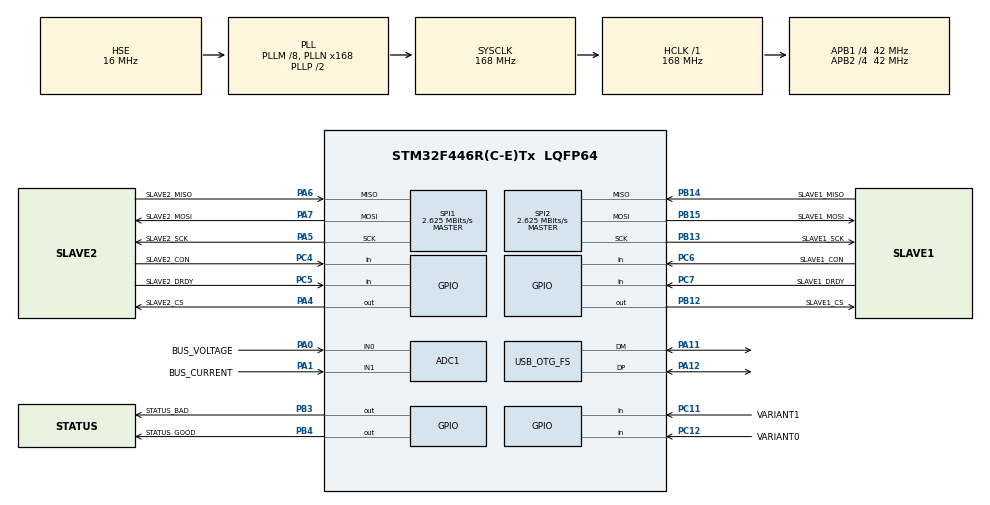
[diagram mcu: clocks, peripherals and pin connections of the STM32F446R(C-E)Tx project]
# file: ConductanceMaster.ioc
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ADC1.Channel-0\#ChannelRegularConversion=ADC_CHANNEL_0
ADC1.Channel-1\#ChannelRegularConversion=ADC_CHANNEL_1
ADC1.Channel-2\#ChannelRegularConversion=ADC_CHANNEL_TEMPSENSOR
ADC1.Channel-3\#ChannelRegularConversion=ADC_CHANNEL_VREFINT
ADC1.ClockPrescaler=ADC_CLOCK_SYNC_PCLK_DIV8
ADC1.ContinuousConvMode=DISABLE
ADC1.DiscontinuousConvMode=DISABLE
ADC1.EOCSelection=ADC_EOC_SEQ_CONV
ADC1.NbrOfConversion=4
ADC1.NbrOfConversionFlag=1
ADC1.Rank-0\#ChannelRegularConversion=1
ADC1.Rank-1\#ChannelRegularConversion=2
ADC1.Rank-2\#ChannelRegularConversion=3
ADC1.Rank-3\#ChannelRegularConversion=4
ADC1.SamplingTime-0\#ChannelRegularConversion=ADC_SAMPLETIME_480CYCLES
ADC1.SamplingTime-1\#ChannelRegularConversion=ADC_SAMPLETIME_480CYCLES
ADC1.SamplingTime-2\#ChannelRegularConversion=ADC_SAMPLETIME_480CYCLES
ADC1.SamplingTime-3\#ChannelRegularConversion=ADC_SAMPLETIME_480CYCLES
ADC1.master=1
Dma.ADC1.0.Direction=DMA_PERIPH_TO_MEMORY
Dma.ADC1.0.FIFOMode=DMA_FIFOMODE_DISABLE
Dma.ADC1.0.Instance=DMA2_Stream0
Dma.ADC1.0.MemDataAlignment=DMA_MDATAALIGN_HALFWORD
Dma.ADC1.0.MemInc=DMA_MINC_ENABLE
Dma.ADC1.0.Mode=DMA_NORMAL
Dma.ADC1.0.PeriphDataAlignment=DMA_PDATAALIGN_HALFWORD
Dma.ADC1.0.PeriphInc=DMA_PINC_DISABLE
Dma.ADC1.0.Priority=DMA_PRIORITY_LOW
Dma.Request0=ADC1
Mcu.Family=STM32F4
Mcu.Name=STM32F446R(C-E)Tx
Mcu.Package=LQFP64
NVIC.DMA2_Stream0_IRQn=true\:0\:0\:false\:false\:true\:false\:true\:true
NVIC.OTG_FS_IRQn=true\:0\:0\:false\:false\:true\:false\:true\:true
NVIC.PriorityGroup=NVIC_PRIORITYGROUP_4
NVIC.TIM1_UP_TIM10_IRQn=true\:0\:0\:false\:false\:true\:true\:true\:true
PA0-WKUP.GPIO_Label=BUS_VOLTAGE
PA0-WKUP.Signal=ADCx_IN0
PA1.GPIO_Label=BUS_CURRENT
PA1.Signal=ADCx_IN1
PA11.Mode=Device_Only
PA11.Signal=USB_OTG_FS_DM
PA12.Mode=Device_Only
PA12.Signal=USB_OTG_FS_DP
PA13.Mode=Serial_Wire
PA13.Signal=SYS_JTMS-SWDIO
PA14.Mode=Serial_Wire
PA14.Signal=SYS_JTCK-SWCLK
PA4.GPIO_Label=SLAVE2_CS
PA4.PinState=GPIO_PIN_SET
PA4.Signal=GPIO_Output
PA5.GPIO_Label=SLAVE2_SCK
PA5.Mode=Full_Duplex_Master
PA5.Signal=SPI1_SCK
PA6.GPIO_Label=SLAVE2_MISO
PA6.Mode=Full_Duplex_Master
PA6.Signal=SPI1_MISO
PA7.GPIO_Label=SLAVE2_MOSI
PA7.Mode=Full_Duplex_Master
PA7.Signal=SPI1_MOSI
PB12.GPIO_Label=SLAVE1_CS
PB12.PinState=GPIO_PIN_SET
PB12.Signal=GPIO_Output
PB13.GPIO_Label=SLAVE1_SCK
PB13.Mode=Full_Duplex_Master
PB13.Signal=SPI2_SCK
PB14.GPIO_Label=SLAVE1_MISO
PB14.Mode=Full_Duplex_Master
PB14.Signal=SPI2_MISO
PB15.GPIO_Label=SLAVE1_MOSI
PB15.Mode=Full_Duplex_Master
PB15.Signal=SPI2_MOSI
PB3.GPIO_Label=STATUS_BAD
PB3.GPIO_ModeDefaultOutputPP=GPIO_MODE_OUTPUT_OD
PB3.GPIO_PuPd=GPIO_NOPULL
PB3.PinState=GPIO_PIN_SET
PB3.Signal=GPIO_Output
PB4.GPIO_Label=STATUS_GOOD
PB4.GPIO_ModeDefaultOutputPP=GPIO_MODE_OUTPUT_OD
PB4.GPIO_PuPd=GPIO_NOPULL
PB4.PinState=GPIO_PIN_SET
PB4.Signal=GPIO_Output
PC11.GPIO_Label=VARIANT1
PC11.GPIO_PuPd=GPIO_PULLUP
PC11.Signal=GPIO_Input
PC12.GPIO_Label=VARIANT0
PC12.GPIO_PuPd=GPIO_PULLUP
PC12.Signal=GPIO_Input
PC4.GPIO_Label=SLAVE2_CON
PC4.GPIO_PuPd=GPIO_PULLUP
PC4.Signal=GPIO_Input
PC5.GPIO_Label=SLAVE2_DRDY
PC5.GPIO_PuPd=GPIO_PULLUP
PC5.Signal=GPIO_Input
PC6.GPIO_Label=SLAVE1_CON
PC6.GPIO_PuPd=GPIO_PULLUP
PC6.Signal=GPIO_Input
PC7.GPIO_Label=SLAVE1_DRDY
PC7.GPIO_PuPd=GPIO_PULLUP
PC7.Signal=GPIO_Input
PH0-OSC_IN.Mode=HSE-External-Clock-Source
PH0-OSC_IN.Signal=RCC_OSC_IN
PH1-OSC_OUT.Mode=HSE-External-Clock-Source
PH1-OSC_OUT.Signal=RCC_OSC_OUT
ProjectManager.HeapSize=0x200
ProjectManager.StackSize=0x400
ProjectManager.TargetToolchain=STM32CubeIDE
RCC.AHBFreq_Value=168000000
RCC.APB1CLKDivider=RCC_HCLK_DIV4
RCC.APB1Freq_Value=42000000
RCC.APB1TimFreq_Value=84000000
RCC.APB2CLKDivider=RCC_HCLK_DIV4
RCC.APB2Freq_Value=42000000
RCC.APB2TimFreq_Value=84000000
RCC.CortexFreq_Value=168000000
RCC.HCLKFreq_Value=168000000
RCC.HSE_VALUE=16000000
RCC.PLLM=8
RCC.PLLN=168
RCC.PLLQ=7
RCC.SYSCLKFreq_VALUE=168000000
RCC.SYSCLKSource=RCC_SYSCLKSOURCE_PLLCLK
RCC.USBFreq_Value=48000000
RCC.VCOOutputFreq_Value=336000000
SH.ADCx_IN0.0=ADC1_IN0,IN0
SH.ADCx_IN1.0=ADC1_IN1,IN1
SPI1.BaudRatePrescaler=SPI_BAUDRATEPRESCALER_16
SPI1.CalculateBaudRate=2.625 MBits/s
SPI1.DataSize=SPI_DATASIZE_16BIT
SPI1.Direction=SPI_DIRECTION_2LINES
SPI1.Mode=SPI_MODE_MASTER
SPI1.VirtualType=VM_MASTER
SPI2.BaudRatePrescaler=SPI_BAUDRATEPRESCALER_16
SPI2.CalculateBaudRate=2.625 MBits/s
SPI2.DataSize=SPI_DATASIZE_16BIT
SPI2.Direction=SPI_DIRECTION_2LINES
SPI2.Mode=SPI_MODE_MASTER
SPI2.VirtualType=VM_MASTER
TIM1.Period=99
TIM1.Prescaler=83
USB_DEVICE.CLASS_NAME_FS=CUSTOM_HID
USB_DEVICE.CONFIGURATION_STRING_CUSTOMHID_FS=Conductance Config
USB_DEVICE.INTERFACE_STRING_CUSTOMHID_FS=Conductance Interface
USB_DEVICE.MANUFACTURER_STRING-CUSTOM_HID_FS=H-BRS/ISF
USB_DEVICE.PRODUCT_STRING_CUSTOMHID_FS=Conductance Board
USB_DEVICE.USBD_SELF_POWERED-CUSTOM_HID_FS=0
USB_DEVICE.VirtualMode-CUSTOM_HID_FS=CustomHid
USB_DEVICE.VirtualModeFS=Custom_Hid_FS
USB_OTG_FS.VirtualMode=Device_Only
VP_ADC1_TempSens_Input.Mode=IN-TempSens
VP_ADC1_Vref_Input.Mode=IN-Vrefint
VP_TIM1_VS_ClockSourceINT.Mode=Internal
VP_USB_DEVICE_VS_USB_DEVICE_CUSTOM_HID_FS.Mode=CUSTOM_HID_FS
board=custom

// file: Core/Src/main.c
/* USER CODE BEGIN Header */
/**
  ******************************************************************************
  * @file           : main.c
  * @brief          : Main program body
  ******************************************************************************
  * @attention
  *
  * <h2><center>&copy; Copyright (c) 2021 STMicroelectronics.
  * All rights reserved.</center></h2>
  *
  * This software component is licensed by ST under BSD 3-Clause license,
  * the "License"; You may not use this file except in compliance with the
  * License. You may obtain a copy of the License at:
  *                        opensource.org/licenses/BSD-3-Clause
  *
  ******************************************************************************
  */
/* USER CODE END Header */
#include "main.h"
#include "usb_device.h"

/* USER CODE BEGIN Includes */
#include "usermain.h"
/* USER CODE END Includes */

ADC_HandleTypeDef hadc1;
DMA_HandleTypeDef hdma_adc1;

SPI_HandleTypeDef hspi1;
SPI_HandleTypeDef hspi2;

TIM_HandleTypeDef htim1;

void SystemClock_Config(void);
static void MX_GPIO_Init(void);
static void MX_DMA_Init(void);
static void MX_ADC1_Init(void);
static void MX_SPI1_Init(void);
static void MX_SPI2_Init(void);
static void MX_TIM1_Init(void);

int main(void)
{

  /* MCU Configuration--------------------------------------------------------*/

  /* Reset of all peripherals, Initializes the Flash interface and the Systick. */
  HAL_Init();

  /* Configure the system clock */
  SystemClock_Config();

  /* Initialize all configured peripherals */
  MX_GPIO_Init();
  MX_DMA_Init();
  MX_SPI1_Init();
  MX_SPI2_Init();
  MX_TIM1_Init();
  MX_USB_DEVICE_Init();
  /* USER CODE BEGIN 2 */
  MX_ADC1_Init(); // Must be called after MX_DMA_Init()
  user_main();
  /* USER CODE END 2 */

  /* Infinite loop */
  while (1)
  {

  }
}

void SystemClock_Config(void)
{
  RCC_OscInitTypeDef RCC_OscInitStruct = {0};
  RCC_ClkInitTypeDef RCC_ClkInitStruct = {0};

  /** Configure the main internal regulator output voltage
  */
  __HAL_RCC_PWR_CLK_ENABLE();
  __HAL_PWR_VOLTAGESCALING_CONFIG(PWR_REGULATOR_VOLTAGE_SCALE1);

  /** Initializes the RCC Oscillators according to the specified parameters
  * in the RCC_OscInitTypeDef structure.
  */
  RCC_OscInitStruct.OscillatorType = RCC_OSCILLATORTYPE_HSE;
  RCC_OscInitStruct.HSEState = RCC_HSE_BYPASS;
  RCC_OscInitStruct.PLL.PLLState = RCC_PLL_ON;
  RCC_OscInitStruct.PLL.PLLSource = RCC_PLLSOURCE_HSE;
  RCC_OscInitStruct.PLL.PLLM = 8;
  RCC_OscInitStruct.PLL.PLLN = 168;
  RCC_OscInitStruct.PLL.PLLP = RCC_PLLP_DIV2;
  RCC_OscInitStruct.PLL.PLLQ = 7;
  RCC_OscInitStruct.PLL.PLLR = 2;
  if (HAL_RCC_OscConfig(&RCC_OscInitStruct) != HAL_OK)
  {
    Error_Handler();
  }

  /** Initializes the CPU, AHB and APB buses clocks
  */
  RCC_ClkInitStruct.ClockType = RCC_CLOCKTYPE_HCLK|RCC_CLOCKTYPE_SYSCLK
                              |RCC_CLOCKTYPE_PCLK1|RCC_CLOCKTYPE_PCLK2;
  RCC_ClkInitStruct.SYSCLKSource = RCC_SYSCLKSOURCE_PLLCLK;
  RCC_ClkInitStruct.AHBCLKDivider = RCC_SYSCLK_DIV1;
  RCC_ClkInitStruct.APB1CLKDivider = RCC_HCLK_DIV4;
  RCC_ClkInitStruct.APB2CLKDivider = RCC_HCLK_DIV4;

  if (HAL_RCC_ClockConfig(&RCC_ClkInitStruct, FLASH_LATENCY_5) != HAL_OK)
  {
    Error_Handler();
  }
}

static void MX_ADC1_Init(void)
{

  ADC_ChannelConfTypeDef sConfig = {0};

  /** Configure the global features of the ADC (Clock, Resolution, Data Alignment and number of conversion)
  */
  hadc1.Instance = ADC1;
  hadc1.Init.ClockPrescaler = ADC_CLOCK_SYNC_PCLK_DIV8;
  hadc1.Init.Resolution = ADC_RESOLUTION_12B;
  hadc1.Init.ScanConvMode = ENABLE;
  hadc1.Init.ContinuousConvMode = DISABLE;
  hadc1.Init.DiscontinuousConvMode = DISABLE;
  hadc1.Init.ExternalTrigConvEdge = ADC_EXTERNALTRIGCONVEDGE_NONE;
  hadc1.Init.ExternalTrigConv = ADC_SOFTWARE_START;
  hadc1.Init.DataAlign = ADC_DATAALIGN_RIGHT;
  hadc1.Init.NbrOfConversion = 4;
  hadc1.Init.DMAContinuousRequests = DISABLE;
  hadc1.Init.EOCSelection = ADC_EOC_SEQ_CONV;
  if (HAL_ADC_Init(&hadc1) != HAL_OK)
  {
    Error_Handler();
  }

  /** Configure for the selected ADC regular channel its corresponding rank in the sequencer and its sample time.
  */
  sConfig.Channel = ADC_CHANNEL_0;
  sConfig.Rank = 1;
  sConfig.SamplingTime = ADC_SAMPLETIME_480CYCLES;
  if (HAL_ADC_ConfigChannel(&hadc1, &sConfig) != HAL_OK)
  {
    Error_Handler();
  }

  /** Configure for the selected ADC regular channel its corresponding rank in the sequencer and its sample time.
  */
  sConfig.Channel = ADC_CHANNEL_1;
  sConfig.Rank = 2;
  if (HAL_ADC_ConfigChannel(&hadc1, &sConfig) != HAL_OK)
  {
    Error_Handler();
  }

  /** Configure for the selected ADC regular channel its corresponding rank in the sequencer and its sample time.
  */
  sConfig.Channel = ADC_CHANNEL_TEMPSENSOR;
  sConfig.Rank = 3;
  if (HAL_ADC_ConfigChannel(&hadc1, &sConfig) != HAL_OK)
  {
    Error_Handler();
  }

  /** Configure for the selected ADC regular channel its corresponding rank in the sequencer and its sample time.
  */
  sConfig.Channel = ADC_CHANNEL_VREFINT;
  sConfig.Rank = 4;
  if (HAL_ADC_ConfigChannel(&hadc1, &sConfig) != HAL_OK)
  {
    Error_Handler();
  }

}

static void MX_SPI1_Init(void)
{

  /* SPI1 parameter configuration*/
  hspi1.Instance = SPI1;
  hspi1.Init.Mode = SPI_MODE_MASTER;
  hspi1.Init.Direction = SPI_DIRECTION_2LINES;
  hspi1.Init.DataSize = SPI_DATASIZE_16BIT;
  hspi1.Init.CLKPolarity = SPI_POLARITY_LOW;
  hspi1.Init.CLKPhase = SPI_PHASE_1EDGE;
  hspi1.Init.NSS = SPI_NSS_SOFT;
  hspi1.Init.BaudRatePrescaler = SPI_BAUDRATEPRESCALER_16;
  hspi1.Init.FirstBit = SPI_FIRSTBIT_MSB;
  hspi1.Init.TIMode = SPI_TIMODE_DISABLE;
  hspi1.Init.CRCCalculation = SPI_CRCCALCULATION_DISABLE;
  hspi1.Init.CRCPolynomial = 10;
  if (HAL_SPI_Init(&hspi1) != HAL_OK)
  {
    Error_Handler();
  }

}

static void MX_SPI2_Init(void)
{

  /* SPI2 parameter configuration*/
  hspi2.Instance = SPI2;
  hspi2.Init.Mode = SPI_MODE_MASTER;
  hspi2.Init.Direction = SPI_DIRECTION_2LINES;
  hspi2.Init.DataSize = SPI_DATASIZE_16BIT;
  hspi2.Init.CLKPolarity = SPI_POLARITY_LOW;
  hspi2.Init.CLKPhase = SPI_PHASE_1EDGE;
  hspi2.Init.NSS = SPI_NSS_SOFT;
  hspi2.Init.BaudRatePrescaler = SPI_BAUDRATEPRESCALER_16;
  hspi2.Init.FirstBit = SPI_FIRSTBIT_MSB;
  hspi2.Init.TIMode = SPI_TIMODE_DISABLE;
  hspi2.Init.CRCCalculation = SPI_CRCCALCULATION_DISABLE;
  hspi2.Init.CRCPolynomial = 10;
  if (HAL_SPI_Init(&hspi2) != HAL_OK)
  {
    Error_Handler();
  }

}

static void MX_TIM1_Init(void)
{

  TIM_ClockConfigTypeDef sClockSourceConfig = {0};
  TIM_MasterConfigTypeDef sMasterConfig = {0};

  htim1.Instance = TIM1;
  htim1.Init.Prescaler = 83;
  htim1.Init.CounterMode = TIM_COUNTERMODE_UP;
  htim1.Init.Period = 99;
  htim1.Init.ClockDivision = TIM_CLOCKDIVISION_DIV1;
  htim1.Init.RepetitionCounter = 0;
  htim1.Init.AutoReloadPreload = TIM_AUTORELOAD_PRELOAD_DISABLE;
  if (HAL_TIM_Base_Init(&htim1) != HAL_OK)
  {
    Error_Handler();
  }
  sClockSourceConfig.ClockSource = TIM_CLOCKSOURCE_INTERNAL;
  if (HAL_TIM_ConfigClockSource(&htim1, &sClockSourceConfig) != HAL_OK)
  {
    Error_Handler();
  }
  sMasterConfig.MasterOutputTrigger = TIM_TRGO_RESET;
  sMasterConfig.MasterSlaveMode = TIM_MASTERSLAVEMODE_DISABLE;
  if (HAL_TIMEx_MasterConfigSynchronization(&htim1, &sMasterConfig) != HAL_OK)
  {
    Error_Handler();
  }

}

static void MX_DMA_Init(void)
{

  /* DMA controller clock enable */
  __HAL_RCC_DMA2_CLK_ENABLE();

  /* DMA interrupt init */
  /* DMA2_Stream0_IRQn interrupt configuration */
  HAL_NVIC_SetPriority(DMA2_Stream0_IRQn, 0, 0);
  HAL_NVIC_EnableIRQ(DMA2_Stream0_IRQn);

}

static void MX_GPIO_Init(void)
{
  GPIO_InitTypeDef GPIO_InitStruct = {0};

  /* GPIO Ports Clock Enable */
  __HAL_RCC_GPIOC_CLK_ENABLE();
  __HAL_RCC_GPIOH_CLK_ENABLE();
  __HAL_RCC_GPIOA_CLK_ENABLE();
  __HAL_RCC_GPIOB_CLK_ENABLE();
  __HAL_RCC_GPIOD_CLK_ENABLE();

  /*Configure GPIO pin Output Level */
  HAL_GPIO_WritePin(SLAVE2_CS_GPIO_Port, SLAVE2_CS_Pin, GPIO_PIN_SET);

  /*Configure GPIO pin Output Level */
  HAL_GPIO_WritePin(GPIOB, SLAVE1_CS_Pin|STATUS_BAD_Pin|STATUS_GOOD_Pin, GPIO_PIN_SET);

  /*Configure GPIO pins : PC13 PC14 PC15 PC0
                           PC1 PC2 PC3 PC8
                           PC9 PC10 */
  GPIO_InitStruct.Pin = GPIO_PIN_13|GPIO_PIN_14|GPIO_PIN_15|GPIO_PIN_0
                          |GPIO_PIN_1|GPIO_PIN_2|GPIO_PIN_3|GPIO_PIN_8
                          |GPIO_PIN_9|GPIO_PIN_10;
  GPIO_InitStruct.Mode = GPIO_MODE_ANALOG;
  GPIO_InitStruct.Pull = GPIO_NOPULL;
  HAL_GPIO_Init(GPIOC, &GPIO_InitStruct);

  /*Configure GPIO pins : PA2 PA3 PA8 PA9
                           PA10 PA15 */
  GPIO_InitStruct.Pin = GPIO_PIN_2|GPIO_PIN_3|GPIO_PIN_8|GPIO_PIN_9
                          |GPIO_PIN_10|GPIO_PIN_15;
  GPIO_InitStruct.Mode = GPIO_MODE_ANALOG;
  GPIO_InitStruct.Pull = GPIO_NOPULL;
  HAL_GPIO_Init(GPIOA, &GPIO_InitStruct);

  /*Configure GPIO pin : SLAVE2_CS_Pin */
  GPIO_InitStruct.Pin = SLAVE2_CS_Pin;
  GPIO_InitStruct.Mode = GPIO_MODE_OUTPUT_PP;
  GPIO_InitStruct.Pull = GPIO_NOPULL;
  GPIO_InitStruct.Speed = GPIO_SPEED_FREQ_LOW;
  HAL_GPIO_Init(SLAVE2_CS_GPIO_Port, &GPIO_InitStruct);

  /*Configure GPIO pins : SLAVE2_CON_Pin SLAVE2_DRDY_Pin SLAVE1_CON_Pin SLAVE1_DRDY_Pin
                           VARIANT1_Pin VARIANT0_Pin */
  GPIO_InitStruct.Pin = SLAVE2_CON_Pin|SLAVE2_DRDY_Pin|SLAVE1_CON_Pin|SLAVE1_DRDY_Pin
                          |VARIANT1_Pin|VARIANT0_Pin;
  GPIO_InitStruct.Mode = GPIO_MODE_INPUT;
  GPIO_InitStruct.Pull = GPIO_PULLUP;
  HAL_GPIO_Init(GPIOC, &GPIO_InitStruct);

  /*Configure GPIO pins : PB0 PB1 PB2 PB10
                           PB5 PB6 PB7 PB8
                           PB9 */
  GPIO_InitStruct.Pin = GPIO_PIN_0|GPIO_PIN_1|GPIO_PIN_2|GPIO_PIN_10
                          |GPIO_PIN_5|GPIO_PIN_6|GPIO_PIN_7|GPIO_PIN_8
                          |GPIO_PIN_9;
  GPIO_InitStruct.Mode = GPIO_MODE_ANALOG;
  GPIO_InitStruct.Pull = GPIO_NOPULL;
  HAL_GPIO_Init(GPIOB, &GPIO_InitStruct);

  /*Configure GPIO pin : SLAVE1_CS_Pin */
  GPIO_InitStruct.Pin = SLAVE1_CS_Pin;
  GPIO_InitStruct.Mode = GPIO_MODE_OUTPUT_PP;
  GPIO_InitStruct.Pull = GPIO_NOPULL;
  GPIO_InitStruct.Speed = GPIO_SPEED_FREQ_LOW;
  HAL_GPIO_Init(SLAVE1_CS_GPIO_Port, &GPIO_InitStruct);

  /*Configure GPIO pin : PD2 */
  GPIO_InitStruct.Pin = GPIO_PIN_2;
  GPIO_InitStruct.Mode = GPIO_MODE_ANALOG;
  GPIO_InitStruct.Pull = GPIO_NOPULL;
  HAL_GPIO_Init(GPIOD, &GPIO_InitStruct);

  /*Configure GPIO pins : STATUS_BAD_Pin STATUS_GOOD_Pin */
  GPIO_InitStruct.Pin = STATUS_BAD_Pin|STATUS_GOOD_Pin;
  GPIO_InitStruct.Mode = GPIO_MODE_OUTPUT_OD;
  GPIO_InitStruct.Pull = GPIO_NOPULL;
  GPIO_InitStruct.Speed = GPIO_SPEED_FREQ_LOW;
  HAL_GPIO_Init(GPIOB, &GPIO_InitStruct);

}

void Error_Handler(void)
{
  __disable_irq();
  while (1)
  {
  }
}
